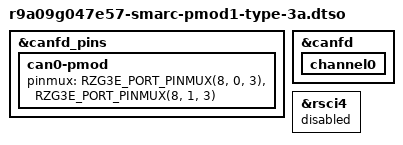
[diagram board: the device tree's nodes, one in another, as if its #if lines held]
// SPDX-License-Identifier: (GPL-2.0-only OR BSD-2-Clause)
/*
 * Device Tree Source for the RZ/G3E SMARC Carrier II EVK PMOD parts
 *
 * [Connection]
 *
 * SMARC Carrier II EVK
 * +------------------------------------------+
 * | PMOD1_3A (PMOD PIN HEADER)               |
 * | SER0_CTS#    (pin1)  (pin7) PMOD1_GPIO10 |
 * | SER0_TX      (pin2)  (pin8) PMOD1_GPIO11 |
 * | SER0_RX      (pin3)  (pin9) PMOD1_GPIO12 |
 * | SER0_RTS#    (pin4)  (pin10)PMOD1_GPIO13 |
 * | GND          (pin5)  (pin11)GND          |
 * | PWR_PMOD1    (pin6)  (pin12)PWR_PMOD1    |
 * +------------------------------------------+
 *
 * Switch settings for RSCI4:
 * - SYS.5: OFF (SW_LCD_EN = 0)
 * - SW_OPT_MUX.4: OFF (SW_SER0_PMOD = 1)
 */

/dts-v1/;
/plugin/;

#include <dt-bindings/pinctrl/renesas,r9a09g047-pinctrl.h>
#include "rzg3e-smarc-switches.h"

/* SW_OFF = RSCI4 UART, SW_ON = native CAN0 on pins 1/4. */
#define PMOD1_CAN0	SW_OFF

#if SW_LCD_EN || !SW_SER0_PMOD
#error "PMOD1 Type 3A requires SW_LCD_EN=0 and SW_SER0_PMOD=1"
#endif

#if PMOD1_CAN0
&canfd_pins {
	can0-pmod {
		pinmux = <RZG3E_PORT_PINMUX(8, 0, 3)>, /* CRX0 */
			 <RZG3E_PORT_PINMUX(8, 1, 3)>; /* CTX0 */
	};
};

&canfd {
	channel0 {
		status = "okay";
	};
};

&rsci4 {
	status = "disabled";
};
#else
&pinctrl {
	rsci4_pins: rsci4 {
		pinmux = <RZG3E_PORT_PINMUX(7, 6, 5)>, /* RXD4 */
			 <RZG3E_PORT_PINMUX(7, 7, 5)>, /* TXD4 */
			 <RZG3E_PORT_PINMUX(8, 0, 6)>, /* CTS4N */
			 <RZG3E_PORT_PINMUX(8, 1, 5)>; /* RTS4N */
		bias-pull-up;
	};
};

&rsci4 {
	pinctrl-0 = <&rsci4_pins>;
	pinctrl-names = "default";
	uart-has-rtscts;
	status = "okay";
};
#endif
